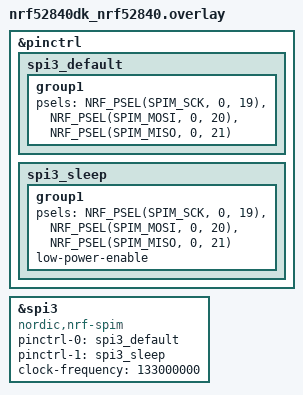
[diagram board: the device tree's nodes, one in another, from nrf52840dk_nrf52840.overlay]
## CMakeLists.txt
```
cmake_minimum_required(VERSION 3.20.0)
find_package(Zephyr REQUIRED HINTS $ENV{ZEPHYR_BASE})

project(p1fats)


add_subdirectory(src/fatfs)
add_subdirectory(src/modules)
add_subdirectory(src/dhara)




include_directories(src)
include_directories(src/fatfs)
include_directories(src/dhara)
include_directories(src/modules)


target_sources(app PRIVATE src/main.c)
target_sources(app PRIVATE src/mt29f_nand_flash.c)
target_sources(app PRIVATE src/mt29f_nand_flash_reg.c)
```

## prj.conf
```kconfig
CONFIG_SPI=y
CONFIG_CBPRINTF_FP_SUPPORT=y
# STEP 1.1 - Enable the custom driver

# STEP 1.2 - Enable application defined syscalls
CONFIG_APPLICATION_DEFINED_SYSCALL=y
CONFIG_LOG=y

CONFIG_LOG_BACKEND_RTT=y
CONFIG_FILE_SYSTEM=y
CONFIG_MAIN_STACK_SIZE=8192
CONFIG_DISK_ACCESS=y
```

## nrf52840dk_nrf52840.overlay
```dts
// To get started, press Ctrl+Space to bring up the completion menu and view the available nodes.

// You can also use the buttons in the sidebar to perform actions on nodes.
// Actions currently available include:

// * Enabling / disabling the node
// * Adding the bus to a bus
// * Removing the node
// * Connecting ADC channels

// For more help, browse the DeviceTree documentation at https://docs.zephyrproject.org/latest/guides/dts/index.html
// You can also visit the nRF DeviceTree extension documentation at https://docs.nordicsemi.com/bundle/nrf-connect-vscode/page/guides/ncs_configure_app.html#devicetree-support-in-the-extension

&pinctrl {
    spi3_default: spi3_default {
        group1 {
            psels = <NRF_PSEL(SPIM_SCK, 0, 19)>,
                    <NRF_PSEL(SPIM_MOSI, 0, 20)>,
                    <NRF_PSEL(SPIM_MISO, 0, 21)>;
                };
    };

    spi3_sleep: spi3_sleep {
        group1 {
            psels = <NRF_PSEL(SPIM_SCK, 0, 19)>,
                    <NRF_PSEL(SPIM_MOSI, 0, 20)>,
                    <NRF_PSEL(SPIM_MISO, 0, 21)>;
            low-power-enable;
        };
    };
};

&spi3 {
    status="okay";
    compatible="nordic,nrf-spim";
    pinctrl-0 = <&spi3_default>;
    pinctrl-1 = <&spi3_sleep>;
    pinctrl-names = "default", "sleep";
    clock-frequency=<133000000>;
      
  
};
```

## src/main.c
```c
/*
 * Copyright (c) 2016 Intel Corporation
 *
 * SPDX-License-Identifier: Apache-2.0
 */

#include "main.h"
#include "ff.h"
#include "ffconf.h"
#include "mem.h"
#include "shell.h"
/** @brief Register the module for logging. */
LOG_MODULE_REGISTER(main, LOG_LEVEL_INF);
FATFS fs; // file system object

int main(void)
{

     
        nrf_gpio_cfg_output(FLASH_TRIGGER);
        nrf_gpio_pin_set(FLASH_TRIGGER);

        //    k_msleep(2000);
        nrf_gpio_cfg_input(FLASH_WP_PIN, NRF_GPIO_PIN_NOPULL);

        /* Hold cpin */
        nrf_gpio_cfg_output(FLASH_HOLD_PIN);
        nrf_gpio_pin_set(FLASH_HOLD_PIN);

        LOG_DBG("spi test started\r\n");
        gpio_pin_configure(gpio0_dev, GPIO0_CS, GPIO_OUTPUT);
        gpio_pin_set(gpio0_dev, GPIO0_CS, 1);

        FRESULT res = f_mount(&fs, "", 1);
        if (FR_OK == res)
        {
                shell_prints_line("f_mount succeeded!");
                FIL fil;
                FRESULT res;
                UINT bw;
                UINT br;

                // Create a new file
                res = f_open(&fil, "tejas1.txt", FA_CREATE_ALWAYS | FA_WRITE);
                if (res == FR_OK)
                {
                        // Write data to the file       
                        char data[200] = "tejas vyas";
                        char read_buffer[200] = "";
                        res = f_write(&fil, data, sizeof(data), &bw);
                        if (res == FR_OK)
                        {
                                printf("File written successfully.\n");
                        }
                        else
                        {
                                printf("Failed to write file. Error code: %d\n", res);
                        }
                        f_close(&fil);

                        // Open the file for reading
                        res = f_open(&fil, "tejas1.txt", FA_READ);
                        if (res != FR_OK)
                        {
                                printf("Failed to open file for reading. Error code: %d\n", res);
                                return -1;
                        }

                        // Read the content of the file
                        res = f_read(&fil, read_buffer, sizeof(data), &br);
                        if (res == FR_OK)
                        {
                                printf("File read successfully. Data: %s\n", read_buffer);
                        }
                        else
                        {
                                printf("Failed to read file. Error code: %d\n", res);
                        }
                }

                else
                {
                        printf("Failed to create file. Error code: %d\n", res);
                }

                res = f_unlink("tejas1.txt");
                if (res == FR_OK)
                {
                        printf("File deleted successfully.\n");
                }
                else
                {
                        printf("Failed to delete file. Error code: %d\n", res);
                }
        }
        else
        {
                shell_printf_line("f_mount failed, result: %d.", res);
        }

        // if filesystem mount failed due to no filesystem, attempt to make it
        if (FR_NO_FILESYSTEM == res)
        {
                shell_prints_line("No filesystem present. Attempting to make file system..");
                uint8_t *work_buffer = mem_alloc(FF_MAX_SS);
                if (!work_buffer)
                {
                        shell_prints_line("Unable to allocate f_mkfs work buffer. File system not created.");
                }
                else
                {
                        // make the file system
                        res = f_mkfs("", 0, work_buffer, FF_MAX_SS);
                        if (FR_OK != res)
                        {
                                shell_printf_line("f_mkfs failed, result: %d.", res); // fs make failure
                        }
                        else
                        {
                                shell_prints_line("f_mkfs succeeded!"); // fs make success
                                // retry mount
                                res = f_mount(&fs, "", 1);
                                if (FR_OK == res)
                                {
                                        shell_prints_line("f_mount succeeded!");
                                }
                                else
                                {
                                        shell_printf_line("f_mount failed, result: %d.", res);
                                }
                        }

                        mem_free(work_buffer);
                }
        }
        return 0;
}
```

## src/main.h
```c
#include <zephyr/kernel.h>
#include <zephyr/device.h>
#include <zephyr/drivers/gpio.h>
#include <zephyr/drivers/spi.h>
#include <zephyr/logging/log.h>
#include <hal/nrf_gpio.h>
#include "mt29f_nand_flash.h"
```

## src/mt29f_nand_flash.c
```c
/*
 * Copyright (c) 2018 Nordic Semiconductor ASA
 *
 * SPDX-License-Identifier: LicenseRef-Nordic-5-Clause
 */

/**@file
 * @defgroup spi_nand_flash SPI NAND Flash Driver
 * @{
 * @brief Implementation of the SPI NAND Flash driver.
 */

// Include necessary headers
#include <zephyr/kernel.h>
#include <zephyr/device.h>
#include <zephyr/drivers/gpio.h>
#include <zephyr/drivers/spi.h>
#include <zephyr/logging/log.h>
#include <hal/nrf_gpio.h>
#include "mt29f_nand_flash.h"
#include "mt29f_nand_flash_reg.h"

/** @brief Register the module for logging. */
LOG_MODULE_REGISTER(spi_flash, LOG_LEVEL_INF);


uint8_t page_main_and_oob_buffer[SPI_NAND_PAGE_SIZE + SPI_NAND_OOB_SIZE];

/**
 * @brief  Initialize the NAND flash.
 * @retval 0 if successful, error code otherwise.
 */
ReturnType MT29F4G_flash_init(void)
{
    k_msleep(2);

    int ret = reset();
    if (SPI_NAND_RET_OK != ret)
    {
        LOG_ERR("unable to reset\n");
        return RESET_ERROR;
    }
    k_msleep(2);
    ret = whoami();
    if (SPI_NAND_RET_OK != ret)
    {
        LOG_ERR("error in reading id\n");
        return READ_ID_ERROR;
    }
    ret = unlock_all_blocks();
    if (SPI_NAND_RET_OK != ret)
    {
        return UNLOCK_ALL_BLOCK_ERROR;
    }
    ret = enable_ecc();
    if (SPI_NAND_RET_OK != ret)
    {
        return ENABLE_ECC_ERROR;
    }
    return SPI_NAND_RET_OK;
}

/**
 * @brief  Write a page to the NAND flash.
 * @param  row: The row address to write to.
 * @param  column: The column address to write to.
 * @param  data_in: The data to be written.
 * @param  write_len: The length of data to write.
 * @retval 0 if successful, error code otherwise.
 */
ReturnType MT29F4G_flash_write_page(row_address_t row, column_address_t column, uint8_t *data_in, size_t write_len)
{
    /* Input validation */
    uint32_t timeout = 0x0;
    if (!validate_row_address(row) || !validate_column_address(column))
    {
        return SPI_NAND_RET_BAD_ADDRESS;
    }
    uint16_t max_write_len = (SPI_NAND_PAGE_SIZE + SPI_NAND_OOB_SIZE) - column;

    if (write_len > max_write_len)
    {
        return SPI_NAND_RET_INVALID_LEN;
    }

    int ret = write_enable(OP_TIMEOUT);

    if (SPI_NAND_RET_OK != ret)
    {
        LOG_ERR("problem in enabling write\n");
        return WRITE_ENABLE_ERROR;
    }

    ret = program_load(column, data_in, write_len, timeout);

    if (SPI_NAND_RET_OK != ret)
    {
        LOG_ERR("error in program load\n");
        return PROGRAM_LOAD_ERROR;
    }

    ret = program_execute(row, timeout);

    if (SPI_NAND_RET_OK != ret)
    {
        LOG_ERR("error in program execute\n");
        return PROGRAM_EXECUTE_ERROR;
    }

    return SPI_NAND_RET_OK;
}

/**
 * @brief  Read a page from the NAND flash.
 * @param  row: The row address to read from.
 * @param  column: The column address to read from.
 * @param  data_out: The data read from the page.
 * @param  read_len: The length of data to read.
 * @retval 0 if successful, error code otherwise.
 */
ReturnType MT29F4G_flash_page_read(row_address_t row, column_address_t column, uint8_t *data_out, size_t read_len)
{
    uint32_t timeout = 0x00;
    uint16_t max_read_len = (SPI_NAND_PAGE_SIZE + SPI_NAND_OOB_SIZE) - column;
    if (!validate_row_address(row) || !validate_column_address(column))
    {
        return SPI_NAND_RET_BAD_ADDRESS;
    }
    if (read_len > max_read_len)
    {
        return SPI_NAND_RET_INVALID_LEN;
    }
    ReturnType ret = page_read(row, OP_TIMEOUT);
    if (SPI_NAND_RET_OK != ret)
    {
        return READ_PAGE_ERROR;
    }
    ret = read_from_cache(column, data_out, read_len, timeout);
    if (SPI_NAND_RET_OK != ret)
    {
        return READ_FROM_CACHE_ERROR;
    }
    return ret;
}




/**
 * @brief  To erase the Block.
 * @param  row : block address.
 * @retval SPI_NAND_RET_OK in case of success, an error code otherwise.
 */
ReturnType MT29F4G_flash_block_erase(row_address_t row)
{
    uint32_t timeout = 0x00;
    row.page = 0;
    if (!validate_row_address(row))
    {
        return SPI_NAND_RET_BAD_ADDRESS;
    }

    int ret = write_enable(OP_TIMEOUT);
    if (ret)
    {
        return WRITE_ENABLE_ERROR;
    }
    ret = block_erase(row, timeout);
    if(SPI_NAND_RET_OK!=ret){
        return BLOCK_ERASE_ERROR;
    }
    return SPI_NAND_RET_OK;
}

/**
 * @brief Checks if a given block is bad.
 * @note Block operation -- page component of row address is ignored
 * @return SPI_NAND_RET_OK          if good block,
 *         SPI_NAND_RET_BAD_ADDRESS if invalid page or block number
 *         SPI_NAND_RET_INVALID_LEN if provide buffer lenght.
 */
ReturnType MT29F4G_flash_is_bad_block(row_address_t row, bool *is_bad)
{
    uint8_t bad_block_mark[6];
    int ret = MT29F4G_flash_page_read(row, 4096, bad_block_mark, sizeof(bad_block_mark));
    if (ret)
    {
        return FLASH_READ_ERROR;
    }
    if (BAD_BLOCK_MARK == bad_block_mark[0] || BAD_BLOCK_MARK == bad_block_mark[5])
    {
        *is_bad = true;
    }
    else
    {
        *is_bad = false;
    }
    return SPI_NAND_RET_OK;
}



/**
 * @brief  To mark the bad block.
 * @param  row : block address.
 * @retval SPI_NAND_RET_OK in case of success, an error code otherwise.
 */
ReturnType MT29F4G_flash_flashblock_mark_bad(row_address_t row)
{
    ReturnType ret = 0;
    uint8_t bad_block_mark[2] = {BAD_BLOCK_MARK, BAD_BLOCK_MARK};
    ret = MT29F4G_flash_write_page(row, SPI_NAND_PAGE_SIZE, bad_block_mark, sizeof(bad_block_mark));
    if (SPI_NAND_RET_OK != ret)
    {
        return SPI_NAND_RET_BAD_SPI;
    }

    return SPI_NAND_RET_OK;
}

/**
 * @brief
 * @param
 * @param
 * @retval SPI_NAND_RET_OK in case of success, an error code otherwise.
 */
ReturnType MT29F4G_flash_flashpage_is_free(row_address_t row, bool *is_free)
{

    uint32_t comp_word = 0xffffffff;

    int ret = MT29F4G_flash_page_read(row, 0x00, page_main_and_oob_buffer, sizeof(page_main_and_oob_buffer));
    if (ret)
    {
        return FLASH_READ_ERROR;
    }
    *is_free = true;

    for (int i = 0; i < sizeof(page_main_and_oob_buffer); i += sizeof(comp_word))
    {
        if (0 != memcmp(&comp_word, &page_main_and_oob_buffer[i], sizeof(comp_word)))
        {
            *is_free = false;
            break;
        }
    }
    return SPI_NAND_RET_OK;
}

ReturnType MT29F4G_flash_page_copy(row_address_t src, row_address_t dest)
{
    uint32_t timeout = 0;
    uint8_t dummy_byte = 0;
    if (!validate_row_address(src) ||
        !validate_row_address(dest))
    {
        return SPI_NAND_RET_BAD_ADDRESS;
    }

    int ret = page_read(src, OP_TIMEOUT);
    if (SPI_NAND_RET_OK != ret)
    {
        return ret;
    }

    ret = write_enable(timeout);
    if (SPI_NAND_RET_OK != ret)
    {
        return WRITE_ENABLE_ERROR;
    }
    ret = program_load_random_data(0, &dummy_byte, 0, timeout);
    if (SPI_NAND_RET_OK != ret)
    {
        return SPI_NAND_RET_BAD_SPI;
    }

    ret = program_execute(dest, timeout);
    if (SPI_NAND_RET_OK != ret)
    {
        return PROGRAM_EXECUTE_ERROR;
    }
    return SPI_NAND_RET_OK;
}

ReturnType MT29F4G_flash_chip_erase(){
    bool is_bad;
    for (int i = 0; i < SPI_NAND_BLOCKS_PER_LUN + 4; i++) {
        // get bad block flag
        row_address_t row = {.block = i, .page = 0};
        int ret = MT29F4G_flash_is_bad_block(row, &is_bad);
        if (SPI_NAND_RET_OK != ret) return ret;

        // erase if good block
        if (!is_bad) {
            int ret = MT29F4G_flash_block_erase(row);
            if (SPI_NAND_RET_OK != ret) return ret;
        }
        else{
            LOG_INF("bad block is %d\n",i);
            MT29F4G_flash_block_erase(row);
        }
    }

    // if we made it here, nothing returned a bad status
    return SPI_NAND_RET_OK;

}
// Implement function prototypes declared in the header file

/**
 * @}
 */
```

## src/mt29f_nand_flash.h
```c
/*
 * Copyright (c) 2018 Nordic Semiconductor ASA
 *
 * SPDX-License-Identifier: LicenseRef-Nordic-5-Clause
 */

#include <zephyr/kernel.h>
#include <zephyr/device.h>
#include <zephyr/drivers/gpio.h>
#include <zephyr/drivers/spi.h>
#include <zephyr/logging/log.h>
#include <hal/nrf_gpio.h>

#ifndef SPI_NAND_FLASH_H_
#define SPI_NAND_FLASH_H_

/**@file
 * @defgroup spi_nand_flash SPI NAND Flash Driver API
 * @{
 * @brief API for the SPI NAND Flash driver.
 */

// Include necessary headers
#include <stdio.h>
#include <stdbool.h>

#ifdef __cplusplus
extern "C"
{
#endif

#define EIGHTKFREQUENCY 8000000

    static struct spi_config spi_cfg = {
        .frequency = 8000000,                            // Set the SPI bus frequency to 8 MHz
        .operation = SPI_WORD_SET(8) | SPI_TRANSFER_MSB, // Set SPI operation mode: 8-bit words, MSB first
        .slave = 0,                                      // Specify the slave device ID
    };
#define SPI0_NODE DT_NODELABEL(spi3)
    static const struct device *spi0_dev = DEVICE_DT_GET(SPI0_NODE);
#define GPIO0_NODE DT_NODELABEL(gpio0)
#define GPIO0_CS 17

    static const struct device *gpio0_dev = DEVICE_DT_GET(GPIO0_NODE);

#define SLEEP_TIME_MS 1000

#define FLASH_WP_PIN NRF_GPIO_PIN_MAP(0, 22) // IO_2

#define FLASH_HOLD_PIN NRF_GPIO_PIN_MAP(0, 23) // IO_3
#define FLASH_TRIGGER NRF_GPIO_PIN_MAP(0, 25)  // flash trigger

#define BAD_BLOCK_MARK 0x00

// status value
#define ECC_STATUS_NO_ERR 0b000
#define ECC_STATUS_1_3_NO_REFRESH 0b001
#define ECC_STATUS_4_6_REFRESH 0b011
#define ECC_STATUS_7_8_REFRESH 0b101
#define ECC_STATUS_NOT_CORRECTED 0b010

    /* Manufacture ID and Device ID */
    typedef enum
    {
        MFR_ID_MICRON = 0x2C,
        DEVICE_ID_1G_1V8 = 0x35,

    } mfrId_deviceId;

#define SPI_NAND_OOB_SIZE 256
#define SPI_NAND_PAGE_SIZE 4096
#define SPI_NAND_PAGES_PER_BLOCK 64
#define SPI_NAND_BLOCKS_PER_LUN 2048
#define SPI_NAND_MAX_PAGE_ADDRESS (SPI_NAND_PAGES_PER_BLOCK - 1) /* zero-indexed */
#define SPI_NAND_MAX_BLOCK_ADDRESS (SPI_NAND_BLOCKS_PER_LUN - 1) /* zero-indexed */

#define SPI_NAND_LOG2_PAGE_SIZE 12
#define SPI_NAND_LOG2_PAGES_PER_BLOCK 6

    /**
     *@brief SPI return statuses
     */
    typedef enum
    {
        SPI_NAND_RET_OK = 0,
        SPI_NAND_RET_BAD_SPI = -1,
        SPI_NAND_RET_TIMEOUT = -2,
        SPI_NAND_RET_DEVICE_ID = -3,
        SPI_NAND_RET_BAD_ADDRESS = -4,
        SPI_NAND_RET_INVALID_LEN = -5,
        SPI_NAND_RET_ECC_REFRESH = -6,
        SPI_NAND_RET_ECC_ERR = -7,
        SPI_NAND_RET_P_FAIL = -8,
        SPI_NAND_RET_E_FAIL = -9,
        RESET_ERROR = -10,
        READ_ID_ERROR = -11,
        UNLOCK_ALL_BLOCK_ERROR = -12,
        ENABLE_ECC_ERROR = -13,
        WRITE_ENABLE_ERROR = -14,
        PROGRAM_LOAD_ERROR = -15,
        PROGRAM_EXECUTE_ERROR = -16,
        READ_PAGE_ERROR = -17,
        READ_FROM_CACHE_ERROR = -18,
        GET_FEATURE_ERROR = -19,
        SET_FEATURE_ERROR = -20,
        OIP_POLL_ERROR = -21,
        BLOCK_ERASE_ERROR = -22,
        FLASH_READ_ERROR = -23,
        PROGRAM_LOAD_RANDOM_DATA_ERROR = -24,
        STATUS_FAIL = -25,
    } ReturnType;

#define OP_TIMEOUT 3000

    typedef enum
    {
        READ_ID_TRANS_LEN = 4,
        READ_ID_MFR_INDEX = 2,
        READ_ID_DEVICE_INDEX = 3,
        FEATURE_TRANS_LEN = 3,
        FEATURE_REG_INDEX = 1,
        FEATURE_DATA_INDEX = 2,
        PAGE_READ_TRANS_LEN = 4,
        READ_FROM_CACHE_TRANS_LEN = 4,
        PROGRAM_LOAD_TRANS_LEN = 3,
        PROGRAM_EXECUTE_TRANS_LEN = 4,
        BLOCK_ERASE_TRANS_LEN = 4,
        PROGRAM_LOAD_RANDOM_DATA_TRANS_LEN = 3,

    } length_index;

    typedef enum
    {
        FEATURE_REG_BLOCK_LOCK = 0xA0,
        FEATURE_REG_CONFIGURATION = 0xB0,
        FEATURE_REG_STATUS = 0xC0,
    } Register;

    // Commands
    // cmd
    enum
    {
        CMD_RESET = 0xFF,                   /*RESET COMMAND*/
        CMD_READ_ID = 0x9F,                 /*READ ID COMMAND*/
        CMD_SET_FEATURE = 0x1F,             /*SET FEATURE COMMAND*/
        CMD_GET_FEATURE = 0x0F,             /*GET FEATURE COMMAND*/
        CMD_PAGE_READ = 0x13,               /*READ PAGE COMMAND*/
        CMD_READ_FROM_CACHE = 0x03,         /*READ FROM CACHE COMMAND*/
        CMD_WRITE_ENABLE = 0x06,            /*WRITE ENABLE COMMAND*/
        CMD_PROGRAM_LOAD = 0x02,            /*LOAD PROGRAM COMMAND*/
        CMD_PROGRAM_EXECUTE = 0x10,         /*RUN PROGRAM COMMAND*/
        CMD_BLOCK_ERASE = 0xD8,             /*ERASE BLOCK COMMAND*/
        CMD_PROGRAM_LOAD_RANDOM_DATA = 0x84 /*LOAD RANDOM DATA COMMAND*/
    };

    /** @brief Structure representing the configuration feature register. */
    typedef union
    {
        uint8_t whole;
        struct
        {
            uint8_t : 1;
            uint8_t CFG0 : 1;
            uint8_t : 2;
            uint8_t ECC_EN : 1;
            uint8_t LOT_EN : 1;
            uint8_t CFG1 : 1;
            uint8_t CFG2 : 1;
        };
    } feature_reg_configuration_t;

    /** @brief Structure representing a row address in NAND flash. */
    typedef union
    {
        uint32_t whole;
        struct
        {
            uint32_t page : 6;   /* Valid range 0-63  */
            uint32_t block : 26; /* Valid range 0-2047 */
        };
    } row_address_t;

    /** @brief Type representing a column address in NAND flash. */
    typedef uint16_t column_address_t;

    /** @brief Structure representing the block lock feature register. */
    typedef union
    {
        uint8_t whole;
        struct
        {
            uint8_t : 1;
            uint8_t WP_HOLD_DISABLE : 1;
            uint8_t TB : 1;
            uint8_t BP0 : 1;
            uint8_t BP1 : 1;
            uint8_t BP2 : 1;
            uint8_t BP3 : 1;
            uint8_t BRWD : 1;
        };
    } feature_reg_block_lock_t;

    /** @brief Structure representing the status feature register. */
    typedef union
    {
        uint8_t whole;
        struct
        {
            uint8_t OIP : 1;
            uint8_t WEL : 1;
            uint8_t E_FAIL : 1;
            uint8_t P_FAIL : 1;
            uint8_t ECCS0_3 : 3;
            uint8_t CRBSY : 1;
        };
    } feature_reg_status_t;

#define CS_SELECT(pin)                   \
    do                                   \
    {                                    \
        gpio_pin_set(gpio0_dev, pin, 0); \
    } while (0)

#define CS_DESELECT(pin)                 \
    do                                   \
    {                                    \
        gpio_pin_set(gpio0_dev, pin, 1); \
    } while (0)

    ReturnType MT29F4G_flash_init(void);
    ReturnType MT29F4G_flash_write_page(row_address_t row, column_address_t column, uint8_t *data_in, size_t write_len);
    ReturnType MT29F4G_flash_page_read(row_address_t row, column_address_t column, uint8_t *data_out, size_t read_len);
    ReturnType MT29F4G_flash_block_erase(row_address_t row);
    ReturnType MT29F4G_flash_is_bad_block(row_address_t row, bool *is_bad);
    ReturnType MT29F4G_flash_flashblock_mark_bad(row_address_t row);
    ReturnType MT29F4G_flash_flashpage_is_free(row_address_t row, bool *is_free);
    ReturnType MT29F4G_flash_page_copy(row_address_t src, row_address_t dest);
    ReturnType MT29F4G_flash_chip_erase(void);

#ifdef __cplusplus
}
#endif

/**
 * @}
 */

#endif /* SPI_NAND_FLASH_H_ */
```

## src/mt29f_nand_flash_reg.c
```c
#include <zephyr/kernel.h>
#include <zephyr/device.h>
#include <zephyr/drivers/gpio.h>
#include <zephyr/drivers/spi.h>
#include <zephyr/logging/log.h>
#include <hal/nrf_gpio.h>
#include "mt29f_nand_flash_reg.h"
#include "mt29f_nand_flash.h"

LOG_MODULE_REGISTER(spi_flash_reg, LOG_LEVEL_INF);

/**
 * @brief  Row address validation.
 * @param  row: The row address to validate.
 * @retval true if valid, false otherwise.
 */
bool validate_row_address(row_address_t row)
{
    if ((row.block > SPI_NAND_MAX_BLOCK_ADDRESS) || (row.page > SPI_NAND_MAX_PAGE_ADDRESS))
    {
        return false;
    }
    else
    {
        return true;
    }
}

/**
 * @brief  Column address validation.
 * @param  column: The column address to validate.
 * @retval true if valid, false otherwise.
 */
bool validate_column_address(column_address_t column)
{
    if (column >= (SPI_NAND_PAGE_SIZE + SPI_NAND_OOB_SIZE))
    {
        return false;
    }
    else
    {
        return true;
    }
}

/**
 * @brief  Read a feature from the NAND flash.
 * @param  reg: The feature register to read.
 * @param  data_out: The data read from the feature register.
 * @param  timeout: Timeout duration.
 * @retval 0 if successful, error code otherwise.
 */
ReturnType get_feature(uint8_t reg, uint8_t *data_out, uint32_t timeout)
{
    uint8_t tx_data[FEATURE_TRANS_LEN] = {0};
    uint8_t rx_data[FEATURE_TRANS_LEN] = {0};
    tx_data[0] = CMD_GET_FEATURE;
    tx_data[FEATURE_REG_INDEX] = reg;
    struct spi_buf tx_buf = {.buf = tx_data, .len = sizeof(tx_data)};
    struct spi_buf rx_buf = {.buf = rx_data, .len = sizeof(rx_data)};

    struct spi_buf_set tx_buf_set = {.buffers = &tx_buf, .count = 1};
    struct spi_buf_set rx_buf_set = {.buffers = &rx_buf, .count = 1};
    CS_SELECT(GPIO0_CS);

    int ret = spi_transceive(spi0_dev, &spi_cfg, &tx_buf_set, &rx_buf_set);

    CS_DESELECT(GPIO0_CS);
    if (ret < 0)
    {
        LOG_ERR("spi_transceive_dt() failed, err %d", ret);
        return SPI_NAND_RET_BAD_SPI;
    }

    // If good return, write data out
    *data_out = rx_data[FEATURE_DATA_INDEX];

    return SPI_NAND_RET_OK;
}

/**
 * @brief  Write a feature to the NAND flash.
 * @param  reg: The feature register to write to.
 * @param  data: The data to write to the feature register.
 * @param  timeout: Timeout duration.
 * @retval 0 if successful, error code otherwise.
 */
ReturnType set_feature(uint8_t reg, uint8_t data, uint32_t timeout)
{
    uint8_t tx_data[FEATURE_TRANS_LEN] = {0};
    tx_data[0] = CMD_SET_FEATURE;
    tx_data[FEATURE_REG_INDEX] = reg;
    tx_data[FEATURE_DATA_INDEX] = data;
    struct spi_buf tx_buf = {.buf = tx_data, .len = sizeof(tx_data)};
    struct spi_buf_set tx_buf_set = {.buffers = &tx_buf, .count = 1};

    CS_SELECT(GPIO0_CS);
    int ret = spi_write(spi0_dev, &spi_cfg, &tx_buf_set);
    CS_DESELECT(GPIO0_CS);

    if (SPI_NAND_RET_OK != ret)
    {
        return SPI_NAND_RET_BAD_SPI;
    }
    return SPI_NAND_RET_OK;
}




/**
 * @brief  To poll the OPERATION IN PROCESS flag of the Status register.
 * @param  status_out : Pointer to the status reg variable.
 * @param  timeout    : timeout value.
 * @retval SPI_NAND_RET_OK in case of success, an error code otherwise.
 */
ReturnType poll_for_oip_clear(feature_reg_status_t *status_out, uint32_t timeout)
{
    unsigned long long start_time = k_uptime_get();
    timeout = timeout + 100;
    unsigned long long get_feature_timeout = k_uptime_get();
    int ret;

    while (k_uptime_get() - start_time < timeout)
    {

        ret = get_feature(FEATURE_REG_STATUS, &status_out->whole, get_feature_timeout);

        if (ret)
        {
            return SPI_NAND_RET_BAD_SPI;
        }

        else if (0 == status_out->OIP)
        {
            return SPI_NAND_RET_OK;
        }
        else if (status_out->OIP)
        {
            continue;
        }
    }
    return SPI_NAND_RET_TIMEOUT;
}




/**
 * @brief  Perform a software reset of the NAND flash.
 * @retval 0 if successful, error code otherwise.
 */
ReturnType reset(void)
{
    int err;
    /* Setup Command */

    uint8_t tx_data[1] = {0};
    tx_data[0] = CMD_RESET;

    struct spi_buf tx_spi_buf = {.buf = tx_data, .len = sizeof(tx_data)};
    struct spi_buf_set spi_tx_buffer_set = {.buffers = &tx_spi_buf, .count = 1};

    CS_SELECT(GPIO0_CS);
    err = spi_write(spi0_dev, &spi_cfg, &spi_tx_buffer_set);
    CS_DESELECT(GPIO0_CS);

    if (err < 0)
    {
        LOG_ERR("Reset failed\r\n");
        return SPI_NAND_RET_BAD_SPI;
    }
    else
    {
        LOG_INF("Successfully reset\r\n");
        return SPI_NAND_RET_OK;
    }

    feature_reg_status_t status;
    int ret = poll_for_oip_clear(&status, OP_TIMEOUT);
    if (SPI_NAND_RET_OK != ret)
    {
        return SPI_NAND_RET_BAD_SPI;
    }
    return SPI_NAND_RET_OK;
}




/**
 * @brief  Read the manufacturer and device ID from the NAND flash.
 * @retval 0 if successful, error code otherwise.
 */
ReturnType whoami(void)    
{
    int err;
    /* Setup Command */
    uint8_t tx_data[READ_ID_TRANS_LEN + 2] = {0};
    uint8_t rx_data[READ_ID_TRANS_LEN + 2] = {0};

    tx_data[0] = 0x9f;

    struct spi_buf tx_spi_buf = {.buf = tx_data, .len = sizeof(tx_data)};
    struct spi_buf_set spi_tx_buffer_set = {.buffers = &tx_spi_buf, .count = 1};

    struct spi_buf rx_spi_buf = {.buf = rx_data, .len = sizeof(rx_data)};
    struct spi_buf_set spi_rx_buffer_set = {.buffers = &rx_spi_buf, .count = 1};

    CS_SELECT(GPIO0_CS);

    err = spi_write(spi0_dev, &spi_cfg, &spi_tx_buffer_set);
    err = spi_read(spi0_dev, &spi_cfg, &spi_rx_buffer_set);

    CS_DESELECT(GPIO0_CS);

    if (err < 0)
    {
        LOG_ERR("Read Id failed: %d\n", err);
        return err;
    }

    LOG_INF("FLASH MFR ID :  0x%x 0x%x\r\n", rx_data[2], rx_data[3]);
    return err;
}




/**
 * @brief  Unlock all blocks in the NAND flash.
 * @retval 0 if successful, error code otherwise.
 */
ReturnType unlock_all_blocks(void)
{
    int ret;
    feature_reg_block_lock_t unlock_all, readback;
    unlock_all.whole = 0;
    readback.whole = 0;
    ret = get_feature(FEATURE_REG_BLOCK_LOCK, &unlock_all.whole, OP_TIMEOUT);
    if (ret)
    {
        return ret;
    }
    unlock_all.TB = 0;
    unlock_all.BP0 = 0;
    unlock_all.BP1 = 0;
    unlock_all.BP2 = 0;
    unlock_all.BP3 = 0;
    ret = set_feature(FEATURE_REG_BLOCK_LOCK, unlock_all.whole, OP_TIMEOUT);
    if (SPI_NAND_RET_OK != ret)
    {
        return SET_FEATURE_ERROR;
    }

    ret = get_feature(FEATURE_REG_BLOCK_LOCK, &readback.whole, OP_TIMEOUT);
    if (SPI_NAND_RET_OK != ret)
    {
        return GET_FEATURE_ERROR;
    }
    return SPI_NAND_RET_OK;
}




/**
 * @brief  Enable ECC on the NAND flash.
 * @retval 0 if successful, error code otherwise.
 */
ReturnType enable_ecc(void)
{
    int ret = 0;
    feature_reg_configuration_t ecc_enable = {.whole = 0};
    ret = get_feature(FEATURE_REG_CONFIGURATION, &ecc_enable.whole, OP_TIMEOUT);
    if (SPI_NAND_RET_OK != ret)
    {
        return GET_FEATURE_ERROR;
    }
    ecc_enable.ECC_EN = 1;
    ret = set_feature(FEATURE_REG_CONFIGURATION, ecc_enable.whole, OP_TIMEOUT);
    if (SPI_NAND_RET_OK != ret)
    {
        return SET_FEATURE_ERROR;
    }

    return SPI_NAND_RET_OK;
}





/**
 * @brief  Get return code from ECC status.
 * @param  status: The status register data read.
 * @retval Return code based on ECC status.
 */
ReturnType get_ret_from_ecc_status(feature_reg_status_t status)
{
    ReturnType ret;

    switch (status.ECCS0_3)
    {
    case ECC_STATUS_NO_ERR:
    case ECC_STATUS_1_3_NO_REFRESH:
        ret = SPI_NAND_RET_OK;
        break;
    case ECC_STATUS_4_6_REFRESH:
    case ECC_STATUS_7_8_REFRESH:
        ret = SPI_NAND_RET_ECC_REFRESH;
        break;
    case ECC_STATUS_NOT_CORRECTED:
    default:
        ret = SPI_NAND_RET_ECC_ERR;
        break;
    }

    return ret;
}





/**
 * @brief  Perform a page read operation on the NAND flash.
 * @param  row: The row address to read from.
 * @param  timeout: Timeout duration.
 * @retval 0 if successful, error code otherwise.
 */
ReturnType page_read(row_address_t row, uint32_t timeout)
{
    uint8_t tx_data[PAGE_READ_TRANS_LEN];
    tx_data[0] = CMD_PAGE_READ;
    tx_data[1] = row.whole >> 16;
    tx_data[2] = row.whole >> 8;
    tx_data[3] = row.whole;
    struct spi_buf tx_buff = {.buf = tx_data, .len = sizeof(tx_buff)};
    struct spi_buf_set tx_buffer_set = {.buffers = &tx_buff, .count = 1};

    CS_SELECT(GPIO0_CS);
    int ret = spi_write(spi0_dev, &spi_cfg, &tx_buffer_set);
    CS_DESELECT(GPIO0_CS);
    if (SPI_NAND_RET_OK != ret)
    {
        return SPI_NAND_RET_OK;
    }

    feature_reg_status_t status;

    ret = poll_for_oip_clear(&status, timeout);

    if (SPI_NAND_RET_OK != ret)
    {
        return SPI_NAND_RET_BAD_SPI;
    }

    ret = get_ret_from_ecc_status(status);

    if (SPI_NAND_RET_OK != ret)
    {
        return SPI_NAND_RET_BAD_SPI;
    }
    return SPI_NAND_RET_OK;
}




/**
 * @brief  Read data from the NAND flash cache.
 * @param  col: The column address to read from.
 * @param  data_out: The data read from the cache.
 * @param  read_len: The length of data to read.
 * @param  timeout: Timeout duration.
 * @retval 0 if successful, error code otherwise.
 */
ReturnType read_from_cache(column_address_t col, uint8_t *data_out, size_t read_len, uint32_t timeout)
{
    int ret;
    uint8_t tx_data[READ_FROM_CACHE_TRANS_LEN];
    tx_data[0] = CMD_READ_FROM_CACHE;
    tx_data[1] = col >> 8;
    tx_data[2] = col;
    tx_data[3] = 0;

    struct spi_buf tx_buf = {.buf = tx_data, .len = sizeof(tx_data)};
    struct spi_buf_set tx_buf_set = {.buffers = &tx_buf, .count = 1};

    CS_SELECT(GPIO0_CS);
    ret = spi_write(spi0_dev, &spi_cfg, &tx_buf_set);
    if (SPI_NAND_RET_OK != ret)
    {
        return SPI_NAND_RET_BAD_SPI;
    }
    tx_buf.buf = data_out;
    tx_buf.len = read_len;
    tx_buf_set.buffers = &tx_buf;
    tx_buf_set.count = 1;
    ret = spi_read(spi0_dev, &spi_cfg, &tx_buf_set);
    CS_DESELECT(GPIO0_CS);
    if (SPI_NAND_RET_OK != ret)
    {
        return SPI_NAND_RET_BAD_SPI;
    }
    return SPI_NAND_RET_OK;
}




/**
 * @brief  Perform a program load operation on the NAND flash.
 * @param  column: The column address to load the program.
 * @param  data_in: The data to be loaded.
 * @param  write_len: The length of data to write.
 * @param  timeout: Timeout duration.
 * @retval 0 if successful, error code otherwise.
 */
ReturnType program_load(column_address_t column, uint8_t *data_in, size_t write_len, uint32_t timeout)
{
    uint8_t tx_data[PROGRAM_LOAD_TRANS_LEN];
    int ret;
    tx_data[0] = CMD_PROGRAM_LOAD;
    tx_data[1] = column >> 8;
    tx_data[2] = column;

    
    struct spi_buf tx_buf = {.buf = tx_data, .len = sizeof(tx_data)};


    struct spi_buf_set tx_buf_set = {.buffers = &tx_buf, .count = 1};
    struct spi_buf tx_buf1;
    CS_SELECT(GPIO0_CS);
    ret = spi_write(spi0_dev, &spi_cfg, &tx_buf_set);
    if (SPI_NAND_RET_OK != ret)
    {
        return SPI_NAND_RET_BAD_SPI;
    }
    tx_buf1.buf = data_in;
    tx_buf1.len = write_len;

    tx_buf_set.buffers = &tx_buf1;
    tx_buf_set.count = 1;
    ret = spi_write(spi0_dev, &spi_cfg, &tx_buf_set);
    if (SPI_NAND_RET_OK != ret)
    {
        LOG_ERR("writing problem\n");
        return SPI_NAND_RET_BAD_SPI;
    }

    CS_DESELECT(GPIO0_CS);

    return SPI_NAND_RET_OK;
}




/**
 * @brief  Perform a program execute operation on the NAND flash.
 * @param  row: The row address to execute the program.
 * @param  timeout: Timeout duration.
 * @retval 0 if successful, error code otherwise.
 */
ReturnType program_execute(row_address_t row, uint32_t timeout)
{
    uint8_t tx_data[4];
    tx_data[0] = CMD_PROGRAM_EXECUTE;
    tx_data[1] = row.whole >> 16;
    tx_data[2] = row.whole >> 8;
    tx_data[3] = row.whole;
    struct spi_buf tx_buf = {.buf = tx_data, .len = sizeof(tx_data)};
    struct spi_buf_set tx_buf_set = {.buffers = &tx_buf, .count = 1};
    CS_SELECT(GPIO0_CS);
    int ret = spi_write(spi0_dev, &spi_cfg, &tx_buf_set);
    if (ret)
    {
        return -1;
    }

    CS_DESELECT(GPIO0_CS);
    feature_reg_status_t status;

    /* Wait until that operation finishes */
    ret = poll_for_oip_clear(&status, timeout);

    if (ret)
    {
        return SPI_NAND_RET_BAD_SPI; /* If polling failed, return that status */
    }
    else if (status.P_FAIL)
    {
        /**
         *  This bit will also be set if the user attempts to program
         *  a locked or protected region, including the OTP area.
         */
        return STATUS_FAIL; /* Otherwise, check for P_FAIL */
    }
    else
    {
        return SPI_NAND_RET_OK;
    }
}





/**
 * @brief  Enable write operations on the NAND flash.
 * @param  timeout: Timeout duration.
 * @retval 0 if successful, error code otherwise.
 */
ReturnType write_enable(uint32_t timeout)
{
    uint8_t cmd = CMD_WRITE_ENABLE;
    // uint8_t buff[2];
    int ret;
    struct spi_buf tx_buf = {.buf = &cmd, .len = 1};
    struct spi_buf_set tx_buf_set = {.buffers = &tx_buf, .count = 1};

    CS_SELECT(GPIO0_CS);
    ret = spi_write(spi0_dev, &spi_cfg, &tx_buf_set);
    CS_DESELECT(GPIO0_CS);

    if (SPI_NAND_RET_OK != ret)
    {
        return SPI_NAND_RET_BAD_SPI;
    }
    return SPI_NAND_RET_OK;
}





/**
 * @brief  To erase at the block level.
 * @param  row : row address.
 * @param  timeout : timeout value.
 * @retval SPI_NAND_RET_OK in case of success, an error code otherwise.
 */
ReturnType block_erase(row_address_t row, uint32_t timeout)
{
    uint8_t tx_data[4];
    tx_data[0] = 0xD8;
    tx_data[1] = row.whole >> 16;
    tx_data[2] = row.whole >> 8;
    tx_data[3] = row.whole;
    struct spi_buf tx_buf = {.buf = tx_data, .len = sizeof(tx_data)};
    struct spi_buf_set tx_buf_set = {.buffers = &tx_buf, .count = 1};

    CS_SELECT(GPIO0_CS);
    int ret = spi_write(spi0_dev, &spi_cfg, &tx_buf_set);
    CS_DESELECT(GPIO0_CS);
    feature_reg_status_t status;
    ret = poll_for_oip_clear(&status, timeout);
    if (SPI_NAND_RET_OK != ret)
    {
        return SPI_NAND_RET_BAD_SPI;
    }
    else if (status.E_FAIL)
    {
        return STATUS_FAIL;
    }
    else
    {
        return SPI_NAND_RET_OK;
    }
}





/**
 * @brief  To write into the cache register for the specific number of bytes.
 * @param  column    : column address
 * @param  data_in   : Pointer to the buffer ,Pointing the data to be written.
 * @param  write_len : size of the data to be written.
 * @param  timeout   : timeout value.
 * @retval SPI_NAND_RET_OK in case of success, an error code otherwise.
 */
ReturnType program_load_random_data(column_address_t column, uint8_t *data_in, size_t write_len, uint32_t timeout)
{
    uint8_t tx_data[PROGRAM_LOAD_RANDOM_DATA_TRANS_LEN];
    tx_data[0] = CMD_PROGRAM_LOAD_RANDOM_DATA;
    tx_data[1] = column >> 8;
    tx_data[2] = column;

    struct spi_buf tx_buf = {.buf = tx_data, .len = sizeof(tx_data)};
    struct spi_buf_set tx_buf_set = {.buffers = &tx_buf, .count = 1};
    CS_SELECT(GPIO0_CS);
    int ret = spi_write(spi0_dev, &spi_cfg, &tx_buf_set);
    if (SPI_NAND_RET_OK != ret)
    {
        return SPI_NAND_RET_BAD_SPI;
    }
    tx_buf.buf = data_in;
    tx_buf.len = write_len;
    tx_buf_set.buffers = &tx_buf;
    tx_buf_set.count = 1;
    ret = spi_write(spi0_dev, &spi_cfg, &tx_buf_set);
    CS_DESELECT(GPIO0_CS);

    return (SPI_NAND_RET_OK == ret) ? SPI_NAND_RET_OK : SPI_NAND_RET_BAD_SPI;
}
```

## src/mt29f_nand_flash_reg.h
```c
#include<stdio.h>
#include<stdbool.h>
#include"mt29f_nand_flash.h"





bool validate_row_address(row_address_t row); 
bool validate_column_address(column_address_t column);
ReturnType get_feature(uint8_t reg, uint8_t *data_out, uint32_t timeout);
ReturnType set_feature(uint8_t reg, uint8_t data, uint32_t timeout);
ReturnType poll_for_oip_clear(feature_reg_status_t *status_out, uint32_t timeout);
ReturnType reset(void);
ReturnType whoami(void);
ReturnType unlock_all_blocks(void);
ReturnType enable_ecc(void);
ReturnType get_ret_from_ecc_status(feature_reg_status_t status);
ReturnType page_read(row_address_t row, uint32_t timeout);
ReturnType read_from_cache(column_address_t col, uint8_t *data_out, size_t read_len, uint32_t timeout);
ReturnType program_load(column_address_t column, uint8_t *data_in, size_t write_len, uint32_t timeout);
ReturnType program_execute(row_address_t row, uint32_t timeout);
ReturnType write_enable(uint32_t timeout);
ReturnType block_erase(row_address_t row, uint32_t timeout);
ReturnType program_load_random_data(column_address_t column,uint8_t *data_in, size_t write_len, uint32_t timeout);
```
